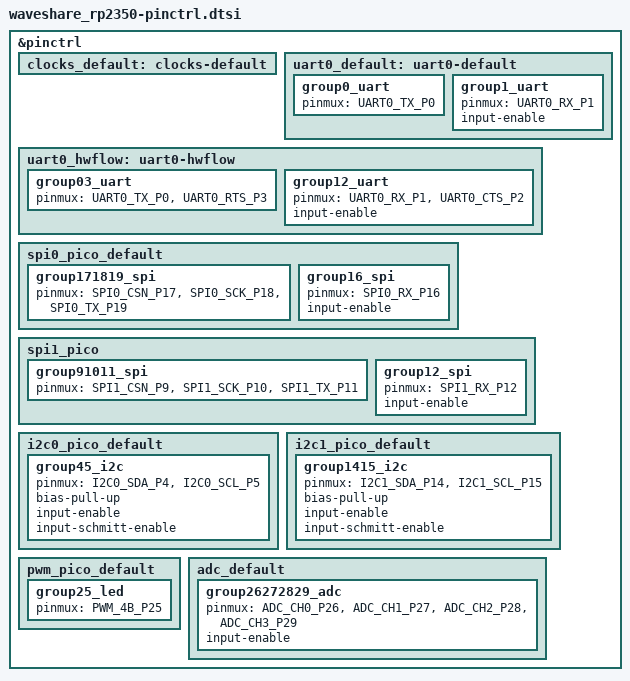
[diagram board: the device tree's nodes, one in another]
/*
 * Copyright (c) 2025 TiaC Systems
 * SPDX-License-Identifier: Apache-2.0
 */

#include <freq.h>
#include <zephyr/dt-bindings/pinctrl/rpi-pico-rp2350a-pinctrl.h>

&pinctrl {
	clocks_default: clocks-default {
		/* no external clocks */
	};

	uart0_default: uart0-default {
		group0_uart {
			pinmux = <UART0_TX_P0>;		/* GP0: UART0_TX */
		};
		group1_uart {
			pinmux = <UART0_RX_P1>;		/* GP1: UART0_RX */
			input-enable;
		};
	};

	uart0_hwflow: uart0-hwflow {
		group03_uart {
			pinmux = <UART0_TX_P0>,		/* GP0: UART0_TX */
				 <UART0_RTS_P3>;	/* GP3: UART0_RTS */
		};
		group12_uart {
			pinmux = <UART0_RX_P1>,		/* GP1: UART0_RX */
				 <UART0_CTS_P2>;	/* GP2: UART0_CTS */
			input-enable;
		};
	};

	spi0_pico_default: spi0_pico_default {
		group171819_spi {
			pinmux = <SPI0_CSN_P17>,	/* GP17: SPI0_CSN */
				 <SPI0_SCK_P18>,	/* GP18: SPI0_SCK */
				 <SPI0_TX_P19>;		/* GP19: SPI0_TX */
		};
		group16_spi {
			pinmux = <SPI0_RX_P16>;		/* GP16: SPI0_RX */
			input-enable;
		};
	};

	spi1_pico: spi1_pico {
		group91011_spi {
			pinmux = <SPI1_CSN_P9>,		/* GP9: SPI1_CSN */
				 <SPI1_SCK_P10>,	/* GP10: SPI1_SCK */
				 <SPI1_TX_P11>;		/* GP11: SPI1_TX */
		};
		group12_spi {
			pinmux = <SPI1_RX_P12>;		/* GP12: SPI1_RX */
			input-enable;
		};
	};

	i2c0_pico_default: i2c0_pico_default {
		group45_i2c {
			pinmux = <I2C0_SDA_P4>,		/* GP4: I2C0_SDA */
				 <I2C0_SCL_P5>;		/* GP5: I2C0_SCL */
			bias-pull-up;
			input-enable;
			input-schmitt-enable;
		};
	};

	i2c1_pico_default: i2c1_pico_default {
		group1415_i2c {
			pinmux = <I2C1_SDA_P14>,	/* GP14: I2C1_SDA */
				 <I2C1_SCL_P15>;	/* GP15: I2C1_SCL */
			bias-pull-up;
			input-enable;
			input-schmitt-enable;
		};
	};

	pwm_pico_default: pwm_pico_default {
		group25_led {
			pinmux = <PWM_4B_P25>;		/* GP25: PWM4CHB (9) */
		};
	};

	adc_default: adc_default {
		group26272829_adc {
			pinmux = <ADC_CH0_P26>,		/* GP26: ADC_CH0 */
				 <ADC_CH1_P27>,		/* GP27: ADC_CH1 */
				 <ADC_CH2_P28>,		/* GP28: ADC_CH2 */
				 <ADC_CH3_P29>;		/* GP29: ADC_CH3 */
			input-enable;
		};
	};
};
